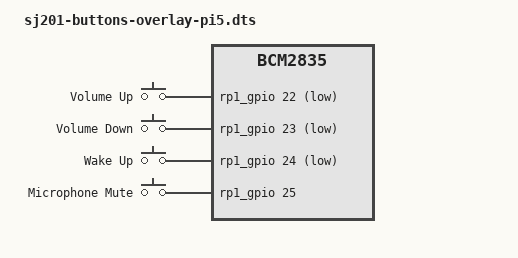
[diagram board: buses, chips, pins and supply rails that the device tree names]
/*
 * Device Tree Button Overlay for SJ-201 Rev6&10 - XMOS VocalFusion 3510-INT
 *
 * This DTO is specifically designed to configure the GPIO pins for button inputs
 * on the SJ-201 board, facilitating user interactions through physical buttons.
 * These configurations include setting up GPIO pins for volume control,
 * wake-up, and microphone mute functionalities.
 *
 * Instructions:
 * Compile this DTO with the following command:
 * dtc -@ -H epapr -O dtb -o sj201-buttons-overlay-pi5.dtbo -Wno-unit_address_vs_reg sj201-buttons-overlay-pi5.dts
 */

/dts-v1/;
/plugin/;

/ {
    compatible = "brcm,bcm2835";

    /* Configure GPIO pins for SJ201 keys */
    fragment@0 {
        target = <&rp1_gpio>;
        __overlay__ {
            sj201_key_pins: sj201_key_pins {
                /* GPIOs 22-24 are configured as momentary switches;
                   GPIO 25 is configured for the Microphone Mute switch. */
                brcm,pins = <22 23 24 25>; // Specify the GPIO pins to configure
                brcm,function = <0>; // Set pins to input mode
                brcm,pull = <0>;     // Disable pull-up/down for these pins
            };
        };
    };

    /* Define GPIO keys for volume control, wake-up, and microphone mute */
    fragment@1 {
        target-path = "/soc";
        __overlay__ {
            sj201_buttons: sj201_buttons {
                compatible = "gpio-keys"; // Define as GPIO keys
                pinctrl-names = "default"; // Use default pin control state
                pinctrl-0 = <&sj201_key_pins>; // Reference the pin configuration from fragment 0
                status = "okay"; // Enable this node
                debounce-interval = <50>; // Set debounce interval to 50ms for all buttons

                /* Volume Up Button */
                button_volume_up: button@22 {
                    gpios = <&rp1_gpio 22 1>; // GPIO 22, active high
                    linux,code = <115>; // KEY_VOLUMEUP to increase volume
                    label = "Volume Up"; // Descriptive label
                };

                /* Volume Down Button */
                button_volume_down: button@23 {
                    gpios = <&rp1_gpio 23 1>; // GPIO 23, active high
                    linux,code = <114>; // KEY_VOLUMEDOWN to decrease volume
                    label = "Volume Down"; // Descriptive label
                };

                /* Wake Up Button */
                button_wake_up: button@24 {
                    gpios = <&rp1_gpio 24 1>; // GPIO 24, active high
                    linux,code = <143>; // KEY_WAKEUP for waking up the system
                    label = "Wake Up"; // Descriptive label
                    gpio-key,wakeup; // Enable this button to wake up the system
                };

                /* Microphone Mute Switch */
                switch_mic_mute: button@25 {
                    gpios = <&rp1_gpio 25 0>; // GPIO 25, active low
                    linux,code = <113>; // KEY_MUTE to mute the microphone
                    label = "Microphone Mute"; // Descriptive label
                };
            };
        };
    };
};
